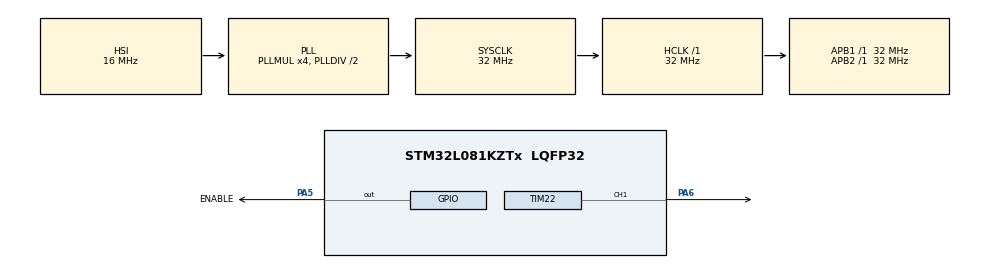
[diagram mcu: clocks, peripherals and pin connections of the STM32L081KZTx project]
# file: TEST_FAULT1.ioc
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Mcu.Family=STM32L0
Mcu.Name=STM32L081KZTx
Mcu.Package=LQFP32
PA13.Mode=Serial_Wire
PA13.Signal=SYS_SWDIO
PA14.Mode=Serial_Wire
PA14.Signal=SYS_SWCLK
PA5.GPIO_Label=ENABLE
PA5.Signal=GPIO_Output
PA6.Signal=S_TIM22_CH1
ProjectManager.HeapSize=0x200
ProjectManager.StackSize=0x400
ProjectManager.TargetToolchain=SW4STM32
RCC.AHBFreq_Value=32000000
RCC.APB1Freq_Value=32000000
RCC.APB1TimFreq_Value=32000000
RCC.APB2Freq_Value=32000000
RCC.APB2TimFreq_Value=32000000
RCC.HCLKFreq_Value=32000000
RCC.HSI16_VALUE=16000000
RCC.HSI_VALUE=16000000
RCC.LSE_VALUE=32768
RCC.MSI_VALUE=2097000
RCC.PLLMUL=RCC_PLLMUL_4
RCC.SYSCLKFreq_VALUE=32000000
RCC.SYSCLKSource=RCC_SYSCLKSOURCE_PLLCLK
RCC.VCOOutputFreq_Value=64000000
SH.S_TIM22_CH1.0=TIM22_CH1,PWM Generation1 CH1
TIM22.AutoReloadPreload=TIM_AUTORELOAD_PRELOAD_ENABLE
TIM22.Channel-PWM\ Generation1\ CH1=TIM_CHANNEL_1
TIM22.Period=129
TIM22.Prescaler=1024
board=custom

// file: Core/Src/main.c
/* USER CODE BEGIN Header */
/**
  ******************************************************************************
  * @file           : main.c
  * @brief          : Main program body
  ******************************************************************************
  * @attention
  *
  * <h2><center>&copy; Copyright (c) 2021 STMicroelectronics.
  * All rights reserved.</center></h2>
  *
  * This software component is licensed by ST under BSD 3-Clause license,
  * the "License"; You may not use this file except in compliance with the
  * License. You may obtain a copy of the License at:
  *                        opensource.org/licenses/BSD-3-Clause
  *
  ******************************************************************************
  */
/* USER CODE END Header */
#include "main.h"

TIM_HandleTypeDef htim22;

void SystemClock_Config(void);
static void MX_GPIO_Init(void);
static void MX_TIM22_Init(void);

int main(void)
{

  /* MCU Configuration--------------------------------------------------------*/

  /* Reset of all peripherals, Initializes the Flash interface and the Systick. */
  HAL_Init();

  /* Configure the system clock */
  SystemClock_Config();

  /* Initialize all configured peripherals */
  MX_GPIO_Init();
  MX_TIM22_Init();
  /* USER CODE BEGIN 2 */
  HAL_TIM_PWM_Start(&htim22, TIM_CHANNEL_1);	//Start PWM generation
  HAL_GPIO_WritePin(ENABLE_GPIO_Port, ENABLE_Pin, GPIO_PIN_RESET);
  TIM22->CCR1 = 120;
  /* USER CODE END 2 */

  /* Infinite loop */
  while (1)
  {

  }
}

void SystemClock_Config(void)
{
  RCC_OscInitTypeDef RCC_OscInitStruct = {0};
  RCC_ClkInitTypeDef RCC_ClkInitStruct = {0};

  /** Configure the main internal regulator output voltage
  */
  __HAL_PWR_VOLTAGESCALING_CONFIG(PWR_REGULATOR_VOLTAGE_SCALE1);
  /** Initializes the RCC Oscillators according to the specified parameters
  * in the RCC_OscInitTypeDef structure.
  */
  RCC_OscInitStruct.OscillatorType = RCC_OSCILLATORTYPE_HSI;
  RCC_OscInitStruct.HSIState = RCC_HSI_ON;
  RCC_OscInitStruct.HSICalibrationValue = RCC_HSICALIBRATION_DEFAULT;
  RCC_OscInitStruct.PLL.PLLState = RCC_PLL_ON;
  RCC_OscInitStruct.PLL.PLLSource = RCC_PLLSOURCE_HSI;
  RCC_OscInitStruct.PLL.PLLMUL = RCC_PLLMUL_4;
  RCC_OscInitStruct.PLL.PLLDIV = RCC_PLLDIV_2;
  if (HAL_RCC_OscConfig(&RCC_OscInitStruct) != HAL_OK)
  {
    Error_Handler();
  }
  /** Initializes the CPU, AHB and APB buses clocks
  */
  RCC_ClkInitStruct.ClockType = RCC_CLOCKTYPE_HCLK|RCC_CLOCKTYPE_SYSCLK
                              |RCC_CLOCKTYPE_PCLK1|RCC_CLOCKTYPE_PCLK2;
  RCC_ClkInitStruct.SYSCLKSource = RCC_SYSCLKSOURCE_PLLCLK;
  RCC_ClkInitStruct.AHBCLKDivider = RCC_SYSCLK_DIV1;
  RCC_ClkInitStruct.APB1CLKDivider = RCC_HCLK_DIV1;
  RCC_ClkInitStruct.APB2CLKDivider = RCC_HCLK_DIV1;

  if (HAL_RCC_ClockConfig(&RCC_ClkInitStruct, FLASH_LATENCY_1) != HAL_OK)
  {
    Error_Handler();
  }
}

static void MX_TIM22_Init(void)
{

  TIM_MasterConfigTypeDef sMasterConfig = {0};
  TIM_OC_InitTypeDef sConfigOC = {0};

  htim22.Instance = TIM22;
  htim22.Init.Prescaler = 1024;
  htim22.Init.CounterMode = TIM_COUNTERMODE_UP;
  htim22.Init.Period = 129;
  htim22.Init.ClockDivision = TIM_CLOCKDIVISION_DIV1;
  htim22.Init.AutoReloadPreload = TIM_AUTORELOAD_PRELOAD_ENABLE;
  if (HAL_TIM_PWM_Init(&htim22) != HAL_OK)
  {
    Error_Handler();
  }
  sMasterConfig.MasterOutputTrigger = TIM_TRGO_RESET;
  sMasterConfig.MasterSlaveMode = TIM_MASTERSLAVEMODE_DISABLE;
  if (HAL_TIMEx_MasterConfigSynchronization(&htim22, &sMasterConfig) != HAL_OK)
  {
    Error_Handler();
  }
  sConfigOC.OCMode = TIM_OCMODE_PWM1;
  sConfigOC.Pulse = 0;
  sConfigOC.OCPolarity = TIM_OCPOLARITY_HIGH;
  sConfigOC.OCFastMode = TIM_OCFAST_DISABLE;
  if (HAL_TIM_PWM_ConfigChannel(&htim22, &sConfigOC, TIM_CHANNEL_1) != HAL_OK)
  {
    Error_Handler();
  }
  HAL_TIM_MspPostInit(&htim22);

}

static void MX_GPIO_Init(void)
{
  GPIO_InitTypeDef GPIO_InitStruct = {0};

  /* GPIO Ports Clock Enable */
  __HAL_RCC_GPIOA_CLK_ENABLE();

  /*Configure GPIO pin Output Level */
  HAL_GPIO_WritePin(ENABLE_GPIO_Port, ENABLE_Pin, GPIO_PIN_RESET);

  /*Configure GPIO pin : ENABLE_Pin */
  GPIO_InitStruct.Pin = ENABLE_Pin;
  GPIO_InitStruct.Mode = GPIO_MODE_OUTPUT_PP;
  GPIO_InitStruct.Pull = GPIO_NOPULL;
  GPIO_InitStruct.Speed = GPIO_SPEED_FREQ_LOW;
  HAL_GPIO_Init(ENABLE_GPIO_Port, &GPIO_InitStruct);

}

void Error_Handler(void)
{
}

/************************ (C) COPYRIGHT STMicroelectronics *****END OF FILE****/
